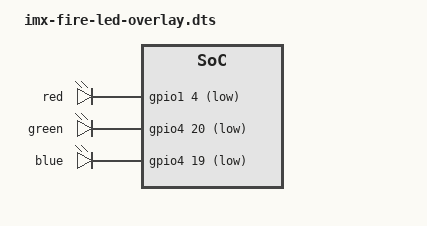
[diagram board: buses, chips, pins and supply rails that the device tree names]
/*
 * Copyright (C) 2019 - All Rights Reserved by 
 * filename : imx-fire-led-overlay.dts
 * brief : Device Tree overlay for EBF6ull led device
 * author : embedfire
 * date : 2019-11-15 
 * version : A001
 */
 /dts-v1/;
 /plugin/;
#include "../imx6ul-pinfunc.h"
#include "../imx6ull-pinfunc.h"
#include "dt-bindings/gpio/gpio.h"
 / {
        fragment@0 {
            target-path = "/";
            __overlay__ {
                normal_led{
                    compatible = "gpio-leds";
                    red {
                        pinctrl-names = "default";
                        pinctrl-0 = <&pinctrl_red>;
                        label = "red";
                        gpios = <&gpio1 4 GPIO_ACTIVE_LOW>;
                        default-state = "off";
                        linux,default-trigger = "none";                       
                    };

                    green {
                        pinctrl-names = "default";
                        pinctrl-0 = <&pinctrl_green>;    
                        label = "green";
                        gpios = <&gpio4 20 GPIO_ACTIVE_LOW>;
                        default-state = "off";
                        linux,default-trigger = "none";                          
                    };

                    blue
                    {
                         pinctrl-names = "default";
                        pinctrl-0 = <&pinctrl_blue>;    
                        label = "blue";
                        gpios = <&gpio4 19 GPIO_ACTIVE_LOW>;
                        default-state = "off";
                        linux,default-trigger = "none";                           
                    };


                };
            };
        };

        fragment@1 {
            target= <&iomuxc>;
            __overlay__{
                pinctrl_red:redgrp{
                    fsl,pins = < MX6UL_PAD_GPIO1_IO04__GPIO1_IO04 0x1b0b0 >;
                };
                pinctrl_green:grngrp{
                    fsl,pins = < MX6UL_PAD_CSI_HSYNC__GPIO4_IO20 0x1b0b0 >;
                };

                pinctrl_blue:bluegrp{
                    fsl,pins = <MX6UL_PAD_CSI_HSYNC__GPIO4_IO20 0x1b0b0 >;
                };
            };
        };

 };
